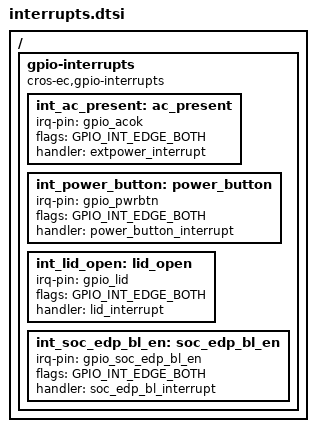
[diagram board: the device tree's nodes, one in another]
/* Copyright 2025 The ChromiumOS Authors
 * Use of this source code is governed by a BSD-style license that can be
 * found in the LICENSE file.
 */

/ {
	gpio-interrupts {
		compatible = "cros-ec,gpio-interrupts";

		int_ac_present: ac_present {
			irq-pin = <&gpio_acok>;
			flags = <GPIO_INT_EDGE_BOTH>;
			handler = "extpower_interrupt";
		};
		int_power_button: power_button {
			irq-pin = <&gpio_pwrbtn>;
			flags = <GPIO_INT_EDGE_BOTH>;
			handler = "power_button_interrupt";
		};
		int_lid_open: lid_open {
			irq-pin = <&gpio_lid>;
			flags = <GPIO_INT_EDGE_BOTH>;
			handler = "lid_interrupt";
		};
		int_soc_edp_bl_en: soc_edp_bl_en {
			irq-pin = <&gpio_soc_edp_bl_en>;
			flags = <GPIO_INT_EDGE_BOTH>;
			handler = "soc_edp_bl_interrupt";
		};
	};
};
